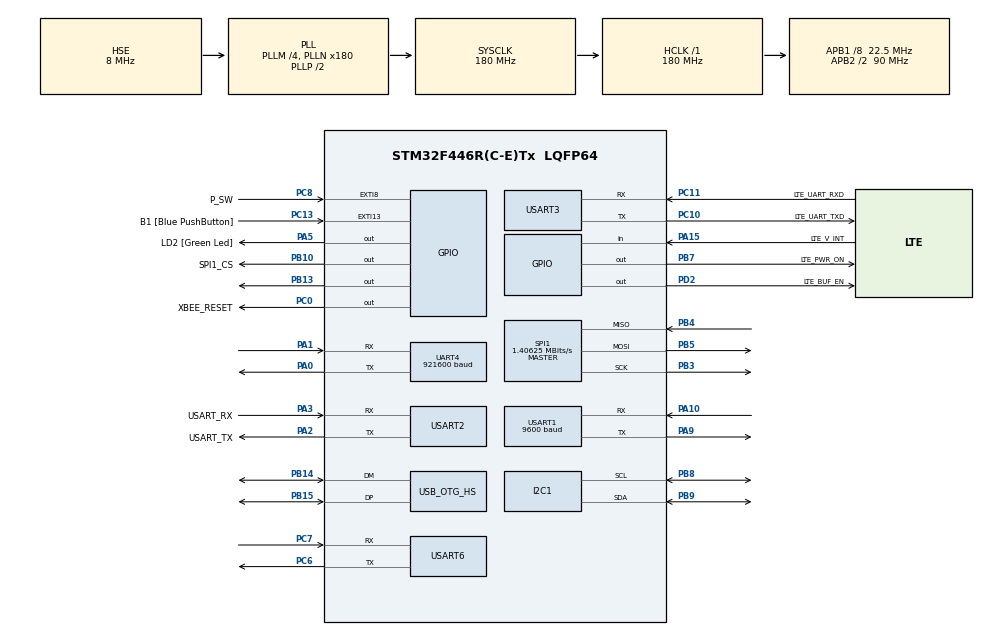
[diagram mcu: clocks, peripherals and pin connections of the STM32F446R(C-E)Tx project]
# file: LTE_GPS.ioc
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ADC1.Channel-0\#ChannelRegularConversion=ADC_CHANNEL_TEMPSENSOR
ADC1.ContinuousConvMode=ENABLE
ADC1.DMAContinuousRequests=ENABLE
ADC1.NbrOfConversionFlag=1
ADC1.Rank-0\#ChannelRegularConversion=1
ADC1.SamplingTime-0\#ChannelRegularConversion=ADC_SAMPLETIME_480CYCLES
ADC1.master=1
Dma.ADC1.4.Direction=DMA_PERIPH_TO_MEMORY
Dma.ADC1.4.FIFOMode=DMA_FIFOMODE_DISABLE
Dma.ADC1.4.Instance=DMA2_Stream0
Dma.ADC1.4.MemDataAlignment=DMA_MDATAALIGN_HALFWORD
Dma.ADC1.4.MemInc=DMA_MINC_ENABLE
Dma.ADC1.4.Mode=DMA_CIRCULAR
Dma.ADC1.4.PeriphDataAlignment=DMA_PDATAALIGN_HALFWORD
Dma.ADC1.4.PeriphInc=DMA_PINC_DISABLE
Dma.ADC1.4.Priority=DMA_PRIORITY_LOW
Dma.Request0=USART3_RX
Dma.Request1=USART3_TX
Dma.Request2=USART1_RX
Dma.Request3=USART1_TX
Dma.Request4=ADC1
Dma.USART1_RX.2.Direction=DMA_PERIPH_TO_MEMORY
Dma.USART1_RX.2.FIFOMode=DMA_FIFOMODE_DISABLE
Dma.USART1_RX.2.Instance=DMA2_Stream2
Dma.USART1_RX.2.MemDataAlignment=DMA_MDATAALIGN_BYTE
Dma.USART1_RX.2.MemInc=DMA_MINC_ENABLE
Dma.USART1_RX.2.Mode=DMA_NORMAL
Dma.USART1_RX.2.PeriphDataAlignment=DMA_PDATAALIGN_BYTE
Dma.USART1_RX.2.PeriphInc=DMA_PINC_DISABLE
Dma.USART1_RX.2.Priority=DMA_PRIORITY_HIGH
Dma.USART1_TX.3.Direction=DMA_MEMORY_TO_PERIPH
Dma.USART1_TX.3.FIFOMode=DMA_FIFOMODE_DISABLE
Dma.USART1_TX.3.Instance=DMA2_Stream7
Dma.USART1_TX.3.MemDataAlignment=DMA_MDATAALIGN_BYTE
Dma.USART1_TX.3.MemInc=DMA_MINC_ENABLE
Dma.USART1_TX.3.Mode=DMA_NORMAL
Dma.USART1_TX.3.PeriphDataAlignment=DMA_PDATAALIGN_BYTE
Dma.USART1_TX.3.PeriphInc=DMA_PINC_DISABLE
Dma.USART1_TX.3.Priority=DMA_PRIORITY_HIGH
Dma.USART3_RX.0.Direction=DMA_PERIPH_TO_MEMORY
Dma.USART3_RX.0.FIFOMode=DMA_FIFOMODE_DISABLE
Dma.USART3_RX.0.Instance=DMA1_Stream1
Dma.USART3_RX.0.MemDataAlignment=DMA_MDATAALIGN_BYTE
Dma.USART3_RX.0.MemInc=DMA_MINC_ENABLE
Dma.USART3_RX.0.Mode=DMA_NORMAL
Dma.USART3_RX.0.PeriphDataAlignment=DMA_PDATAALIGN_BYTE
Dma.USART3_RX.0.PeriphInc=DMA_PINC_DISABLE
Dma.USART3_RX.0.Priority=DMA_PRIORITY_VERY_HIGH
Dma.USART3_TX.1.Direction=DMA_MEMORY_TO_PERIPH
Dma.USART3_TX.1.FIFOMode=DMA_FIFOMODE_DISABLE
Dma.USART3_TX.1.Instance=DMA1_Stream3
Dma.USART3_TX.1.MemDataAlignment=DMA_MDATAALIGN_BYTE
Dma.USART3_TX.1.MemInc=DMA_MINC_ENABLE
Dma.USART3_TX.1.Mode=DMA_NORMAL
Dma.USART3_TX.1.PeriphDataAlignment=DMA_PDATAALIGN_BYTE
Dma.USART3_TX.1.PeriphInc=DMA_PINC_DISABLE
Dma.USART3_TX.1.Priority=DMA_PRIORITY_VERY_HIGH
FATFS._FS_EXFAT=1
FATFS._MAX_SS=4096
FATFS._USE_LFN=1
I2C1.I2C_Mode=I2C_Standard
Mcu.Family=STM32F4
Mcu.Name=STM32F446R(C-E)Tx
Mcu.Package=LQFP64
NVIC.DMA1_Stream1_IRQn=true\:0\:0\:false\:false\:true\:false\:true\:true
NVIC.DMA1_Stream3_IRQn=true\:0\:0\:false\:false\:true\:false\:true\:true
NVIC.DMA2_Stream0_IRQn=true\:0\:0\:false\:false\:true\:false\:true\:true
NVIC.DMA2_Stream2_IRQn=true\:0\:0\:false\:false\:true\:false\:true\:true
NVIC.DMA2_Stream7_IRQn=true\:0\:0\:false\:false\:true\:false\:true\:true
NVIC.EXTI9_5_IRQn=true\:0\:0\:false\:false\:true\:true\:true\:true
NVIC.I2C1_ER_IRQn=true\:0\:0\:false\:false\:true\:true\:true\:true
NVIC.I2C1_EV_IRQn=true\:0\:0\:false\:false\:true\:true\:true\:true
NVIC.OTG_HS_IRQn=true\:0\:0\:false\:false\:true\:false\:true\:true
NVIC.PriorityGroup=NVIC_PRIORITYGROUP_0
NVIC.TIM6_DAC_IRQn=true\:0\:0\:false\:false\:true\:true\:true\:true
NVIC.TIM7_IRQn=true\:0\:0\:false\:false\:true\:true\:true\:true
NVIC.UART4_IRQn=true\:0\:0\:false\:false\:true\:true\:true\:true
NVIC.USART1_IRQn=true\:0\:0\:false\:false\:true\:true\:true\:true
NVIC.USART2_IRQn=true\:0\:0\:false\:false\:true\:true\:true\:true
NVIC.USART3_IRQn=true\:0\:0\:false\:false\:true\:true\:true\:true
NVIC.USART6_IRQn=true\:0\:0\:false\:false\:true\:true\:true\:true
PA0-WKUP.Mode=Asynchronous
PA0-WKUP.Signal=UART4_TX
PA1.Mode=Asynchronous
PA1.Signal=UART4_RX
PA10.Mode=Asynchronous
PA10.Signal=USART1_RX
PA13.GPIO_Label=TMS
PA13.Mode=Serial_Wire
PA13.Signal=SYS_JTMS-SWDIO
PA14.GPIO_Label=TCK
PA14.Mode=Serial_Wire
PA14.Signal=SYS_JTCK-SWCLK
PA15.GPIO_Label=LTE_V_INT
PA15.Signal=GPIO_Input
PA2.GPIO_Label=USART_TX
PA2.Mode=Asynchronous
PA2.Signal=USART2_TX
PA3.GPIO_Label=USART_RX
PA3.Mode=Asynchronous
PA3.Signal=USART2_RX
PA5.GPIO_Label=LD2 [Green Led]
PA5.Signal=GPIO_Output
PA9.Mode=Asynchronous
PA9.Signal=USART1_TX
PB10.GPIO_Label=SPI1_CS
PB10.GPIO_Speed=GPIO_SPEED_FREQ_VERY_HIGH
PB10.PinState=GPIO_PIN_SET
PB10.Signal=GPIO_Output
PB13.PinState=GPIO_PIN_SET
PB13.Signal=GPIO_Output
PB14.Mode=Host_FS
PB14.Signal=USB_OTG_HS_DM
PB15.Mode=Host_FS
PB15.Signal=USB_OTG_HS_DP
PB3.Mode=Full_Duplex_Master
PB3.Signal=SPI1_SCK
PB4.Mode=Full_Duplex_Master
PB4.Signal=SPI1_MISO
PB5.Mode=Full_Duplex_Master
PB5.Signal=SPI1_MOSI
PB7.GPIO_Label=LTE_PWR_ON
PB7.GPIO_ModeDefaultOutputPP=GPIO_MODE_OUTPUT_OD
PB7.GPIO_PuPd=GPIO_NOPULL
PB7.PinState=GPIO_PIN_SET
PB7.Signal=GPIO_Output
PB8.GPIO_Pu=GPIO_NOPULL
PB8.Mode=I2C
PB8.Signal=I2C1_SCL
PB9.GPIO_Pu=GPIO_NOPULL
PB9.Mode=I2C
PB9.Signal=I2C1_SDA
PC0.GPIO_Label=XBEE_RESET
PC0.Signal=GPIO_Output
PC10.GPIO_Label=LTE_UART_TXD
PC10.Mode=Asynchronous
PC10.Signal=USART3_TX
PC11.GPIO_Label=LTE_UART_RXD
PC11.Mode=Asynchronous
PC11.Signal=USART3_RX
PC13.GPIO_Label=B1 [Blue PushButton]
PC13.GPIO_ModeDefaultEXTI=GPIO_MODE_IT_FALLING
PC13.Signal=GPXTI13
PC14-OSC32_IN.Mode=LSE-External-Oscillator
PC14-OSC32_IN.Signal=RCC_OSC32_IN
PC15-OSC32_OUT.Mode=LSE-External-Oscillator
PC15-OSC32_OUT.Signal=RCC_OSC32_OUT
PC6.Mode=Asynchronous
PC6.Signal=USART6_TX
PC7.Mode=Asynchronous
PC7.Signal=USART6_RX
PC8.GPIO_Label=P_SW
PC8.GPIO_PuPd=GPIO_PULLUP
PC8.Signal=GPXTI8
PD2.GPIO_Label=LTE_BUF_EN
PD2.PinState=GPIO_PIN_SET
PD2.Signal=GPIO_Output
PH0-OSC_IN.Mode=HSE-External-Oscillator
PH0-OSC_IN.Signal=RCC_OSC_IN
PH1-OSC_OUT.Mode=HSE-External-Oscillator
PH1-OSC_OUT.Signal=RCC_OSC_OUT
ProjectManager.HeapSize=0x200
ProjectManager.StackSize=0x400
ProjectManager.TargetToolchain=STM32CubeIDE
RCC.48MHZClocksFreq_Value=84000000
RCC.AHBFreq_Value=180000000
RCC.APB1CLKDivider=RCC_HCLK_DIV8
RCC.APB1Freq_Value=22500000
RCC.APB1TimFreq_Value=45000000
RCC.APB2CLKDivider=RCC_HCLK_DIV2
RCC.APB2Freq_Value=90000000
RCC.APB2TimFreq_Value=180000000
RCC.CortexFreq_Value=180000000
RCC.FLatency-AdvancedSettings=FLASH_LATENCY_5
RCC.HCLKFreq_Value=180000000
RCC.HSE_VALUE=8000000
RCC.HSI_VALUE=16000000
RCC.PLLM=4
RCC.PLLN=180
RCC.PLLQ=3
RCC.PLLSAIM=4
RCC.PLLSAIN=96
RCC.PLLSAIP=RCC_PLLSAIP_DIV4
RCC.PLLSourceVirtual=RCC_PLLSOURCE_HSE
RCC.RCC_RTC_Clock_SourceVirtual=RCC_RTCCLKSOURCE_LSE
RCC.SYSCLKFreq_VALUE=180000000
RCC.SYSCLKSource=RCC_SYSCLKSOURCE_PLLCLK
RCC.USBCLockSelection=RCC_CLK48CLKSOURCE_PLLSAIP
RCC.USBFreq_Value=48000000
RCC.VCOOutputFreq_Value=360000000
RTC.Format=RTC_FORMAT_BCD
RTC.WeekDay=RTC_WEEKDAY_WEDNESDAY
RTC.Year=20
SPI1.BaudRatePrescaler=SPI_BAUDRATEPRESCALER_64
SPI1.CalculateBaudRate=1.40625 MBits/s
SPI1.Direction=SPI_DIRECTION_2LINES
SPI1.Mode=SPI_MODE_MASTER
SPI1.VirtualType=VM_MASTER
TIM6.Period=1600-1
TIM6.Prescaler=45000-1
TIM7.Period=500-1
TIM7.Prescaler=45000-1
UART4.BaudRate=921600
UART4.VirtualMode=Asynchronous
USART1.BaudRate=9600
USART1.VirtualMode=VM_ASYNC
USART2.VirtualMode=VM_ASYNC
USART3.VirtualMode=VM_ASYNC
USART6.VirtualMode=VM_ASYNC
USB_HOST.BSP.number=1
USB_HOST.USBH_HandleTypeDef-MSC_HS=hUsbHostHS
USB_HOST.VirtualModeHS=Msc
USB_HOST0.BSP.STBoard=false
USB_HOST0.BSP.api=Unknown
USB_HOST0.BSP.instance=PB13
USB_HOST0.BSP.ip=GPIO
USB_HOST0.BSP.mode=Output
USB_HOST0.BSP.name=Drive_VBUS_HS
USB_HOST0.BSP.solution=PB13
USB_OTG_HS.VirtualMode-Host_FS=Host_FS
VP_ADC1_TempSens_Input.Mode=IN-TempSens
VP_FATFS_VS_USB.Mode=USB
VP_RTC_VS_RTC_Activate.Mode=RTC_Enabled
VP_RTC_VS_RTC_Calendar.Mode=RTC_Calendar
VP_TIM6_VS_ClockSourceINT.Mode=Enable_Timer
VP_TIM7_VS_ClockSourceINT.Mode=Enable_Timer
VP_USB_HOST_VS_USB_HOST_MSC_HS.Mode=MSC_HS
board=NUCLEO-F446RE

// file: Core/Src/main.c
/* USER CODE BEGIN Header */
/**
  ******************************************************************************
  * @file           : main.c
  * @brief          : Main program body
  ******************************************************************************
  * @attention
  *
  * Copyright (c) 2022 STMicroelectronics.
  * All rights reserved.
  *
  * This software is licensed under terms that can be found in the LICENSE file
  * in the root directory of this software component.
  * If no LICENSE file comes with this software, it is provided AS-IS.
  *
  ******************************************************************************
  */
/* USER CODE END Header */
#include "main.h"
#include "fatfs.h"
#include "usb_host.h"

ADC_HandleTypeDef hadc1;
DMA_HandleTypeDef hdma_adc1;

I2C_HandleTypeDef hi2c1;

RTC_HandleTypeDef hrtc;

SPI_HandleTypeDef hspi1;

TIM_HandleTypeDef htim6;
TIM_HandleTypeDef htim7;

UART_HandleTypeDef huart4;
UART_HandleTypeDef huart1;
UART_HandleTypeDef huart2;
UART_HandleTypeDef huart3;
UART_HandleTypeDef huart6;
DMA_HandleTypeDef hdma_usart1_rx;
DMA_HandleTypeDef hdma_usart1_tx;
DMA_HandleTypeDef hdma_usart3_rx;
DMA_HandleTypeDef hdma_usart3_tx;

void SystemClock_Config(void);
static void MX_GPIO_Init(void);
static void MX_USART2_UART_Init(void);
static void MX_RTC_Init(void);
static void MX_DMA_Init(void);
static void MX_USART3_UART_Init(void);
static void MX_TIM6_Init(void);
static void MX_USART1_UART_Init(void);
static void MX_USART6_UART_Init(void);
static void MX_I2C1_Init(void);
static void MX_SPI1_Init(void);
static void MX_TIM7_Init(void);
static void MX_UART4_Init(void);
static void MX_ADC1_Init(void);
void MX_USB_HOST_Process(void);

/* USER CODE BEGIN 0 */
void MSC_Application(void);

/* USER CODE END 0 */

int main(void)
{

  /* MCU Configuration--------------------------------------------------------*/

  /* Reset of all peripherals, Initializes the Flash interface and the Systick. */
  HAL_Init();

  /* Configure the system clock */
  SystemClock_Config();

  /* Initialize all configured peripherals */
  MX_GPIO_Init();
  MX_USART2_UART_Init();
  MX_RTC_Init();
  MX_DMA_Init();
  MX_USART3_UART_Init();
  MX_TIM6_Init();
  MX_USART1_UART_Init();
  MX_USART6_UART_Init();
  MX_I2C1_Init();
  MX_SPI1_Init();
  MX_FATFS_Init();
  MX_USB_HOST_Init();
  MX_TIM7_Init();
  MX_UART4_Init();
  MX_ADC1_Init();
  /* USER CODE BEGIN 2 */

  main_app();
  /* USER CODE END 2 */

  /* Infinite loop */
  while (1)
  {
    MX_USB_HOST_Process();

  }
}

void SystemClock_Config(void)
{
  RCC_OscInitTypeDef RCC_OscInitStruct = {0};
  RCC_ClkInitTypeDef RCC_ClkInitStruct = {0};

  /** Configure the main internal regulator output voltage
  */
  __HAL_RCC_PWR_CLK_ENABLE();
  __HAL_PWR_VOLTAGESCALING_CONFIG(PWR_REGULATOR_VOLTAGE_SCALE1);

  /** Initializes the RCC Oscillators according to the specified parameters
  * in the RCC_OscInitTypeDef structure.
  */
  RCC_OscInitStruct.OscillatorType = RCC_OSCILLATORTYPE_HSE|RCC_OSCILLATORTYPE_LSE;
  RCC_OscInitStruct.HSEState = RCC_HSE_ON;
  RCC_OscInitStruct.LSEState = RCC_LSE_ON;
  RCC_OscInitStruct.PLL.PLLState = RCC_PLL_ON;
  RCC_OscInitStruct.PLL.PLLSource = RCC_PLLSOURCE_HSE;
  RCC_OscInitStruct.PLL.PLLM = 4;
  RCC_OscInitStruct.PLL.PLLN = 180;
  RCC_OscInitStruct.PLL.PLLP = RCC_PLLP_DIV2;
  RCC_OscInitStruct.PLL.PLLQ = 3;
  RCC_OscInitStruct.PLL.PLLR = 2;
  if (HAL_RCC_OscConfig(&RCC_OscInitStruct) != HAL_OK)
  {
    Error_Handler();
  }

  /** Activate the Over-Drive mode
  */
  if (HAL_PWREx_EnableOverDrive() != HAL_OK)
  {
    Error_Handler();
  }

  /** Initializes the CPU, AHB and APB buses clocks
  */
  RCC_ClkInitStruct.ClockType = RCC_CLOCKTYPE_HCLK|RCC_CLOCKTYPE_SYSCLK
                              |RCC_CLOCKTYPE_PCLK1|RCC_CLOCKTYPE_PCLK2;
  RCC_ClkInitStruct.SYSCLKSource = RCC_SYSCLKSOURCE_PLLCLK;
  RCC_ClkInitStruct.AHBCLKDivider = RCC_SYSCLK_DIV1;
  RCC_ClkInitStruct.APB1CLKDivider = RCC_HCLK_DIV8;
  RCC_ClkInitStruct.APB2CLKDivider = RCC_HCLK_DIV2;

  if (HAL_RCC_ClockConfig(&RCC_ClkInitStruct, FLASH_LATENCY_5) != HAL_OK)
  {
    Error_Handler();
  }
}

static void MX_ADC1_Init(void)
{

  ADC_ChannelConfTypeDef sConfig = {0};

  /** Configure the global features of the ADC (Clock, Resolution, Data Alignment and number of conversion)
  */
  hadc1.Instance = ADC1;
  hadc1.Init.ClockPrescaler = ADC_CLOCK_SYNC_PCLK_DIV4;
  hadc1.Init.Resolution = ADC_RESOLUTION_12B;
  hadc1.Init.ScanConvMode = DISABLE;
  hadc1.Init.ContinuousConvMode = ENABLE;
  hadc1.Init.DiscontinuousConvMode = DISABLE;
  hadc1.Init.ExternalTrigConvEdge = ADC_EXTERNALTRIGCONVEDGE_NONE;
  hadc1.Init.ExternalTrigConv = ADC_SOFTWARE_START;
  hadc1.Init.DataAlign = ADC_DATAALIGN_RIGHT;
  hadc1.Init.NbrOfConversion = 1;
  hadc1.Init.DMAContinuousRequests = ENABLE;
  hadc1.Init.EOCSelection = ADC_EOC_SINGLE_CONV;
  if (HAL_ADC_Init(&hadc1) != HAL_OK)
  {
    Error_Handler();
  }

  /** Configure for the selected ADC regular channel its corresponding rank in the sequencer and its sample time.
  */
  sConfig.Channel = ADC_CHANNEL_TEMPSENSOR;
  sConfig.Rank = 1;
  sConfig.SamplingTime = ADC_SAMPLETIME_480CYCLES;
  if (HAL_ADC_ConfigChannel(&hadc1, &sConfig) != HAL_OK)
  {
    Error_Handler();
  }

}

static void MX_I2C1_Init(void)
{

  hi2c1.Instance = I2C1;
  hi2c1.Init.ClockSpeed = 100000;
  hi2c1.Init.DutyCycle = I2C_DUTYCYCLE_2;
  hi2c1.Init.OwnAddress1 = 0;
  hi2c1.Init.AddressingMode = I2C_ADDRESSINGMODE_7BIT;
  hi2c1.Init.DualAddressMode = I2C_DUALADDRESS_DISABLE;
  hi2c1.Init.OwnAddress2 = 0;
  hi2c1.Init.GeneralCallMode = I2C_GENERALCALL_DISABLE;
  hi2c1.Init.NoStretchMode = I2C_NOSTRETCH_DISABLE;
  if (HAL_I2C_Init(&hi2c1) != HAL_OK)
  {
    Error_Handler();
  }

}

static void MX_RTC_Init(void)
{

  RTC_TimeTypeDef sTime = {0};
  RTC_DateTypeDef sDate = {0};

  /** Initialize RTC Only
  */
  hrtc.Instance = RTC;
  hrtc.Init.HourFormat = RTC_HOURFORMAT_24;
  hrtc.Init.AsynchPrediv = 127;
  hrtc.Init.SynchPrediv = 255;
  hrtc.Init.OutPut = RTC_OUTPUT_DISABLE;
  hrtc.Init.OutPutPolarity = RTC_OUTPUT_POLARITY_HIGH;
  hrtc.Init.OutPutType = RTC_OUTPUT_TYPE_OPENDRAIN;
  if (HAL_RTC_Init(&hrtc) != HAL_OK)
  {
    Error_Handler();
  }

  /** Initialize RTC and set the Time and Date
  */
  sTime.Hours = 0x0;
  sTime.Minutes = 0x0;
  sTime.Seconds = 0x0;
  sTime.DayLightSaving = RTC_DAYLIGHTSAVING_NONE;
  sTime.StoreOperation = RTC_STOREOPERATION_RESET;
  if (HAL_RTC_SetTime(&hrtc, &sTime, RTC_FORMAT_BCD) != HAL_OK)
  {
    Error_Handler();
  }
  sDate.WeekDay = RTC_WEEKDAY_WEDNESDAY;
  sDate.Month = RTC_MONTH_JANUARY;
  sDate.Date = 0x1;
  sDate.Year = 0x20;

  if (HAL_RTC_SetDate(&hrtc, &sDate, RTC_FORMAT_BCD) != HAL_OK)
  {
    Error_Handler();
  }

}

static void MX_SPI1_Init(void)
{

  /* SPI1 parameter configuration*/
  hspi1.Instance = SPI1;
  hspi1.Init.Mode = SPI_MODE_MASTER;
  hspi1.Init.Direction = SPI_DIRECTION_2LINES;
  hspi1.Init.DataSize = SPI_DATASIZE_8BIT;
  hspi1.Init.CLKPolarity = SPI_POLARITY_LOW;
  hspi1.Init.CLKPhase = SPI_PHASE_1EDGE;
  hspi1.Init.NSS = SPI_NSS_SOFT;
  hspi1.Init.BaudRatePrescaler = SPI_BAUDRATEPRESCALER_64;
  hspi1.Init.FirstBit = SPI_FIRSTBIT_MSB;
  hspi1.Init.TIMode = SPI_TIMODE_DISABLE;
  hspi1.Init.CRCCalculation = SPI_CRCCALCULATION_DISABLE;
  hspi1.Init.CRCPolynomial = 10;
  if (HAL_SPI_Init(&hspi1) != HAL_OK)
  {
    Error_Handler();
  }

}

static void MX_TIM6_Init(void)
{

  TIM_MasterConfigTypeDef sMasterConfig = {0};

  htim6.Instance = TIM6;
  htim6.Init.Prescaler = 45000-1;
  htim6.Init.CounterMode = TIM_COUNTERMODE_UP;
  htim6.Init.Period = 1600-1;
  htim6.Init.AutoReloadPreload = TIM_AUTORELOAD_PRELOAD_DISABLE;
  if (HAL_TIM_Base_Init(&htim6) != HAL_OK)
  {
    Error_Handler();
  }
  sMasterConfig.MasterOutputTrigger = TIM_TRGO_RESET;
  sMasterConfig.MasterSlaveMode = TIM_MASTERSLAVEMODE_DISABLE;
  if (HAL_TIMEx_MasterConfigSynchronization(&htim6, &sMasterConfig) != HAL_OK)
  {
    Error_Handler();
  }

}

static void MX_TIM7_Init(void)
{

  TIM_MasterConfigTypeDef sMasterConfig = {0};

  htim7.Instance = TIM7;
  htim7.Init.Prescaler = 45000-1;
  htim7.Init.CounterMode = TIM_COUNTERMODE_UP;
  htim7.Init.Period = 500-1;
  htim7.Init.AutoReloadPreload = TIM_AUTORELOAD_PRELOAD_DISABLE;
  if (HAL_TIM_Base_Init(&htim7) != HAL_OK)
  {
    Error_Handler();
  }
  sMasterConfig.MasterOutputTrigger = TIM_TRGO_RESET;
  sMasterConfig.MasterSlaveMode = TIM_MASTERSLAVEMODE_DISABLE;
  if (HAL_TIMEx_MasterConfigSynchronization(&htim7, &sMasterConfig) != HAL_OK)
  {
    Error_Handler();
  }

}

static void MX_UART4_Init(void)
{

  huart4.Instance = UART4;
  huart4.Init.BaudRate = 921600;
  huart4.Init.WordLength = UART_WORDLENGTH_8B;
  huart4.Init.StopBits = UART_STOPBITS_1;
  huart4.Init.Parity = UART_PARITY_NONE;
  huart4.Init.Mode = UART_MODE_TX_RX;
  huart4.Init.HwFlowCtl = UART_HWCONTROL_NONE;
  huart4.Init.OverSampling = UART_OVERSAMPLING_16;
  if (HAL_UART_Init(&huart4) != HAL_OK)
  {
    Error_Handler();
  }

}

static void MX_USART1_UART_Init(void)
{

  huart1.Instance = USART1;
  huart1.Init.BaudRate = 9600;
  huart1.Init.WordLength = UART_WORDLENGTH_8B;
  huart1.Init.StopBits = UART_STOPBITS_1;
  huart1.Init.Parity = UART_PARITY_NONE;
  huart1.Init.Mode = UART_MODE_TX_RX;
  huart1.Init.HwFlowCtl = UART_HWCONTROL_NONE;
  huart1.Init.OverSampling = UART_OVERSAMPLING_16;
  if (HAL_UART_Init(&huart1) != HAL_OK)
  {
    Error_Handler();
  }

}

static void MX_USART2_UART_Init(void)
{

  huart2.Instance = USART2;
  huart2.Init.BaudRate = 115200;
  huart2.Init.WordLength = UART_WORDLENGTH_8B;
  huart2.Init.StopBits = UART_STOPBITS_1;
  huart2.Init.Parity = UART_PARITY_NONE;
  huart2.Init.Mode = UART_MODE_TX_RX;
  huart2.Init.HwFlowCtl = UART_HWCONTROL_NONE;
  huart2.Init.OverSampling = UART_OVERSAMPLING_16;
  if (HAL_UART_Init(&huart2) != HAL_OK)
  {
    Error_Handler();
  }

}

static void MX_USART3_UART_Init(void)
{

  huart3.Instance = USART3;
  huart3.Init.BaudRate = 115200;
  huart3.Init.WordLength = UART_WORDLENGTH_8B;
  huart3.Init.StopBits = UART_STOPBITS_1;
  huart3.Init.Parity = UART_PARITY_NONE;
  huart3.Init.Mode = UART_MODE_TX_RX;
  huart3.Init.HwFlowCtl = UART_HWCONTROL_NONE;
  huart3.Init.OverSampling = UART_OVERSAMPLING_16;
  if (HAL_UART_Init(&huart3) != HAL_OK)
  {
    Error_Handler();
  }

}

static void MX_USART6_UART_Init(void)
{

  huart6.Instance = USART6;
  huart6.Init.BaudRate = 115200;
  huart6.Init.WordLength = UART_WORDLENGTH_8B;
  huart6.Init.StopBits = UART_STOPBITS_1;
  huart6.Init.Parity = UART_PARITY_NONE;
  huart6.Init.Mode = UART_MODE_TX_RX;
  huart6.Init.HwFlowCtl = UART_HWCONTROL_NONE;
  huart6.Init.OverSampling = UART_OVERSAMPLING_16;
  if (HAL_UART_Init(&huart6) != HAL_OK)
  {
    Error_Handler();
  }

}

static void MX_DMA_Init(void)
{

  /* DMA controller clock enable */
  __HAL_RCC_DMA1_CLK_ENABLE();
  __HAL_RCC_DMA2_CLK_ENABLE();

  /* DMA interrupt init */
  /* DMA1_Stream1_IRQn interrupt configuration */
  HAL_NVIC_SetPriority(DMA1_Stream1_IRQn, 0, 0);
  HAL_NVIC_EnableIRQ(DMA1_Stream1_IRQn);
  /* DMA1_Stream3_IRQn interrupt configuration */
  HAL_NVIC_SetPriority(DMA1_Stream3_IRQn, 0, 0);
  HAL_NVIC_EnableIRQ(DMA1_Stream3_IRQn);
  /* DMA2_Stream0_IRQn interrupt configuration */
  HAL_NVIC_SetPriority(DMA2_Stream0_IRQn, 0, 0);
  HAL_NVIC_EnableIRQ(DMA2_Stream0_IRQn);
  /* DMA2_Stream2_IRQn interrupt configuration */
  HAL_NVIC_SetPriority(DMA2_Stream2_IRQn, 0, 0);
  HAL_NVIC_EnableIRQ(DMA2_Stream2_IRQn);
  /* DMA2_Stream7_IRQn interrupt configuration */
  HAL_NVIC_SetPriority(DMA2_Stream7_IRQn, 0, 0);
  HAL_NVIC_EnableIRQ(DMA2_Stream7_IRQn);

}

static void MX_GPIO_Init(void)
{
  GPIO_InitTypeDef GPIO_InitStruct = {0};

  /* GPIO Ports Clock Enable */
  __HAL_RCC_GPIOC_CLK_ENABLE();
  __HAL_RCC_GPIOH_CLK_ENABLE();
  __HAL_RCC_GPIOA_CLK_ENABLE();
  __HAL_RCC_GPIOB_CLK_ENABLE();
  __HAL_RCC_GPIOD_CLK_ENABLE();

  /*Configure GPIO pin Output Level */
  HAL_GPIO_WritePin(XBEE_RESET_GPIO_Port, XBEE_RESET_Pin, GPIO_PIN_RESET);

  /*Configure GPIO pin Output Level */
  HAL_GPIO_WritePin(LD2_GPIO_Port, LD2_Pin, GPIO_PIN_RESET);

  /*Configure GPIO pin Output Level */
  HAL_GPIO_WritePin(GPIOB, SPI1_CS_Pin|GPIO_PIN_13|LTE_PWR_ON_Pin, GPIO_PIN_SET);

  /*Configure GPIO pin Output Level */
  HAL_GPIO_WritePin(LTE_BUF_EN_GPIO_Port, LTE_BUF_EN_Pin, GPIO_PIN_SET);

  /*Configure GPIO pin : B1_Pin */
  GPIO_InitStruct.Pin = B1_Pin;
  GPIO_InitStruct.Mode = GPIO_MODE_IT_FALLING;
  GPIO_InitStruct.Pull = GPIO_NOPULL;
  HAL_GPIO_Init(B1_GPIO_Port, &GPIO_InitStruct);

  /*Configure GPIO pin : XBEE_RESET_Pin */
  GPIO_InitStruct.Pin = XBEE_RESET_Pin;
  GPIO_InitStruct.Mode = GPIO_MODE_OUTPUT_PP;
  GPIO_InitStruct.Pull = GPIO_NOPULL;
  GPIO_InitStruct.Speed = GPIO_SPEED_FREQ_LOW;
  HAL_GPIO_Init(XBEE_RESET_GPIO_Port, &GPIO_InitStruct);

  /*Configure GPIO pin : LD2_Pin */
  GPIO_InitStruct.Pin = LD2_Pin;
  GPIO_InitStruct.Mode = GPIO_MODE_OUTPUT_PP;
  GPIO_InitStruct.Pull = GPIO_NOPULL;
  GPIO_InitStruct.Speed = GPIO_SPEED_FREQ_LOW;
  HAL_GPIO_Init(LD2_GPIO_Port, &GPIO_InitStruct);

  /*Configure GPIO pin : SPI1_CS_Pin */
  GPIO_InitStruct.Pin = SPI1_CS_Pin;
  GPIO_InitStruct.Mode = GPIO_MODE_OUTPUT_PP;
  GPIO_InitStruct.Pull = GPIO_NOPULL;
  GPIO_InitStruct.Speed = GPIO_SPEED_FREQ_VERY_HIGH;
  HAL_GPIO_Init(SPI1_CS_GPIO_Port, &GPIO_InitStruct);

  /*Configure GPIO pin : PB13 */
  GPIO_InitStruct.Pin = GPIO_PIN_13;
  GPIO_InitStruct.Mode = GPIO_MODE_OUTPUT_PP;
  GPIO_InitStruct.Pull = GPIO_NOPULL;
  GPIO_InitStruct.Speed = GPIO_SPEED_FREQ_LOW;
  HAL_GPIO_Init(GPIOB, &GPIO_InitStruct);

  /*Configure GPIO pin : P_SW_Pin */
  GPIO_InitStruct.Pin = P_SW_Pin;
  GPIO_InitStruct.Mode = GPIO_MODE_IT_RISING;
  GPIO_InitStruct.Pull = GPIO_PULLUP;
  HAL_GPIO_Init(P_SW_GPIO_Port, &GPIO_InitStruct);

  /*Configure GPIO pin : LTE_V_INT_Pin */
  GPIO_InitStruct.Pin = LTE_V_INT_Pin;
  GPIO_InitStruct.Mode = GPIO_MODE_INPUT;
  GPIO_InitStruct.Pull = GPIO_NOPULL;
  HAL_GPIO_Init(LTE_V_INT_GPIO_Port, &GPIO_InitStruct);

  /*Configure GPIO pin : LTE_BUF_EN_Pin */
  GPIO_InitStruct.Pin = LTE_BUF_EN_Pin;
  GPIO_InitStruct.Mode = GPIO_MODE_OUTPUT_PP;
  GPIO_InitStruct.Pull = GPIO_NOPULL;
  GPIO_InitStruct.Speed = GPIO_SPEED_FREQ_LOW;
  HAL_GPIO_Init(LTE_BUF_EN_GPIO_Port, &GPIO_InitStruct);

  /*Configure GPIO pin : LTE_PWR_ON_Pin */
  GPIO_InitStruct.Pin = LTE_PWR_ON_Pin;
  GPIO_InitStruct.Mode = GPIO_MODE_OUTPUT_OD;
  GPIO_InitStruct.Pull = GPIO_NOPULL;
  GPIO_InitStruct.Speed = GPIO_SPEED_FREQ_LOW;
  HAL_GPIO_Init(LTE_PWR_ON_GPIO_Port, &GPIO_InitStruct);

  /* EXTI interrupt init*/
  HAL_NVIC_SetPriority(EXTI9_5_IRQn, 0, 0);
  HAL_NVIC_EnableIRQ(EXTI9_5_IRQn);

}

void Error_Handler(void)
{
  __disable_irq();
  while (1)
  {
  }
}
